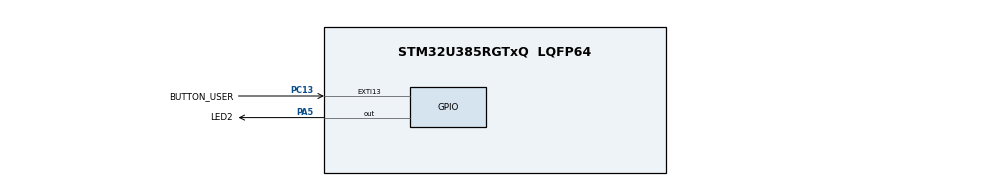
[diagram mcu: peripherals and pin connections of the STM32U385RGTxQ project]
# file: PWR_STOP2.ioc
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CORTEX_M33_NS.userName=CORTEX_M33
Mcu.Family=STM32U3
Mcu.Name=STM32U385RGTxQ
Mcu.Package=LQFP64
NVIC.EXTI13_IRQn=true\:0\:0\:false\:false\:true\:true\:true\:true
NVIC.PriorityGroup=NVIC_PRIORITYGROUP_4
PA5.GPIO_Label=LED2
PA5.Signal=GPIO_Output
PC13.GPIO_Label=BUTTON_USER
PC13.GPIO_ModeDefaultEXTI=GPIO_MODE_IT_RISING
PC13.GPIO_PuPd=GPIO_PULLDOWN
PC13.Signal=GPXTI13
ProjectManager.HeapSize=0x200
ProjectManager.StackSize=0x400
ProjectManager.TargetToolchain=EWARM V9.20
RCC.ADCFreq_Value=96000000
RCC.AHBFreq_Value=96000000
RCC.APB1Freq_Value=96000000
RCC.APB1TimFreq_Value=96000000
RCC.APB2Freq_Value=96000000
RCC.APB2TimFreq_Value=96000000
RCC.APB3Freq_Value=96000000
RCC.CortexFreq_Value=12000000
RCC.HCLKFreq_Value=96000000
RCC.HSE_VALUE=16000000
RCC.HSI48_VALUE=48000000
RCC.HSI_VALUE=16000000
RCC.LSE_VALUE=32768
RCC.LSIDIV_VALUE=32000
RCC.MSISDIV=RCC_MSI_DIV1
RCC.MSI_VALUE=96000000
RCC.PWR_Regulator_Voltage_Scale=PWR_REGULATOR_VOLTAGE_SCALE1
RCC.SYSCLKFreq_VALUE=96000000
RCC.USBFreq_Value=96000000
VP_ICACHE_VS_ICACHE.Mode=DirectMappedCache
VP_PWR_VS_DBSignals.Mode=DisableDeadBatterySignals
VP_PWR_VS_LPOM.Mode=PowerOptimisation
VP_PWR_VS_SECSignals.Mode=Security/Privilege
board=custom

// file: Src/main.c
/* USER CODE BEGIN Header */
/**
  ******************************************************************************
  * @file    PWR/PWR_STOP2/Src/main.c
  * @author  MCD Application Team
  * @brief   This sample code shows how to use STM32U3xx PWR HAL API to enter
  *          and exit the stop 2 mode using RTC.
  ******************************************************************************
  * @attention
  *
  * Copyright (c) 2024 STMicroelectronics.
  * All rights reserved.
  *
  * This software is licensed under terms that can be found in the LICENSE file
  * in the root directory of this software component.
  * If no LICENSE file comes with this software, it is provided AS-IS.
  *
  ******************************************************************************
  */
/* USER CODE END Header */
#include "main.h"

/* USER CODE BEGIN Includes */
#include "stm32u3xx_nucleo.h"
/* USER CODE END Includes */

/* USER CODE BEGIN PV */
/* Private variables ---------------------------------------------------------*/
#define LED_TOGGLE_DELAY         100
static __IO uint32_t TimingDelay;
/* USER CODE END PV */

void SystemClock_Config(void);
static void MX_GPIO_Init(void);
static void MX_ICACHE_Init(void);
/* USER CODE BEGIN PFP */
/* Private function prototypes -----------------------------------------------*/
/* USER CODE END PFP */

int main(void)
{

  /* MCU Configuration--------------------------------------------------------*/

  /* Reset of all peripherals, Initializes the Flash interface and the Systick. */
  HAL_Init();

  /* USER CODE BEGIN Init */

  /* Configure LD2 */
  BSP_LED_Init(LD2);
  /* USER CODE END Init */

  /* Configure the system clock */
  SystemClock_Config();

  /* USER CODE BEGIN SysInit */

  /* Enable the SMPS regulator to improve power efficiency*/
  if(HAL_PWREx_ConfigSupply(PWR_SMPS_SUPPLY) != HAL_OK)
  {
    Error_Handler();
  }

  /* User push-button (External line 13) will be used to wakeup the system from Stop mode */
  BSP_PB_Init(BUTTON_USER, BUTTON_MODE_EXTI);
  /* USER CODE END SysInit */

  /* Initialize all configured peripherals */
  MX_GPIO_Init();
  MX_ICACHE_Init();

  /* Infinite loop */
  while (1)
  {

    /* USER CODE BEGIN 3 */
    /* Insert 5 second delay */
    HAL_Delay(5000);
    /* Turn off LD2 */
    BSP_LED_Off(LD2);

    /* Suspend Tick increment to prevent wakeup by Systick interrupt.         */
    /* Otherwise the Systick interrupt will wake up the device within 1ms     */
    /* (HAL time base).                                                       */
    HAL_SuspendTick();

    /* Enter STOP 2 mode */
    /* A current leakage can be observed while supplying the MCU from an external source and not supplying the STLink
       (unplugged). To fix this leakage, you can configure the pin PA13 as Analog, however, the connection with the
       debugger is lost. */

    HAL_PWR_EnterSTOPMode(PWR_LOWPOWERMODE_STOP2, PWR_STOPENTRY_WFI);

    /* ... STOP 2 mode ... */

    /* Configure the system clock */
    SystemClock_Config();

    /* Resume Tick interrupt if disabled prior to STOP mode entry */
    HAL_ResumeTick();

  }
  /* USER CODE END 3 */
}

void SystemClock_Config(void)
{
  RCC_OscInitTypeDef RCC_OscInitStruct = {0};
  RCC_ClkInitTypeDef RCC_ClkInitStruct = {0};

  /** Enable Epod Booster
  */
  if (HAL_RCCEx_EpodBoosterClkConfig(RCC_EPODBOOSTER_SOURCE_MSIS, RCC_EPODBOOSTER_DIV1) != HAL_OK)
  {
    Error_Handler();
  }
  if (HAL_PWREx_EnableEpodBooster() != HAL_OK)
  {
    Error_Handler();
  }

  /** Configure the main internal regulator output voltage
  */
  if (HAL_PWREx_ControlVoltageScaling(PWR_REGULATOR_VOLTAGE_SCALE1) != HAL_OK)
  {
    Error_Handler();
  }

  /** Set Flash latency before increasing MSIS
  */
  __HAL_FLASH_SET_LATENCY(FLASH_LATENCY_2);

  /** Initializes the CPU, AHB and APB buses clocks
  */
  RCC_OscInitStruct.OscillatorType = RCC_OSCILLATORTYPE_MSIS;
  RCC_OscInitStruct.MSISState = RCC_MSI_ON;
  RCC_OscInitStruct.MSISSource = RCC_MSI_RC0;
  RCC_OscInitStruct.MSISDiv = RCC_MSI_DIV1;
  if (HAL_RCC_OscConfig(&RCC_OscInitStruct) != HAL_OK)
  {
    Error_Handler();
  }

  /** Initializes the CPU, AHB and APB buses clocks
  */
  RCC_ClkInitStruct.ClockType = RCC_CLOCKTYPE_HCLK|RCC_CLOCKTYPE_SYSCLK
                              |RCC_CLOCKTYPE_PCLK1|RCC_CLOCKTYPE_PCLK2
                              |RCC_CLOCKTYPE_PCLK3;
  RCC_ClkInitStruct.SYSCLKSource = RCC_SYSCLKSOURCE_MSIS;
  RCC_ClkInitStruct.AHBCLKDivider = RCC_SYSCLK_DIV1;
  RCC_ClkInitStruct.APB1CLKDivider = RCC_HCLK_DIV1;
  RCC_ClkInitStruct.APB2CLKDivider = RCC_HCLK_DIV1;
  RCC_ClkInitStruct.APB3CLKDivider = RCC_HCLK_DIV1;

  if (HAL_RCC_ClockConfig(&RCC_ClkInitStruct, FLASH_LATENCY_2) != HAL_OK)
  {
    Error_Handler();
  }
}

static void MX_ICACHE_Init(void)
{

  /** Enable instruction cache in 1-way (direct mapped cache)
  */
  if (HAL_ICACHE_ConfigAssociativityMode(ICACHE_1WAY) != HAL_OK)
  {
    Error_Handler();
  }
  if (HAL_ICACHE_Enable() != HAL_OK)
  {
    Error_Handler();
  }

}

static void MX_GPIO_Init(void)
{
  GPIO_InitTypeDef GPIO_InitStruct = {0};

  /* GPIO Ports Clock Enable */
  __HAL_RCC_GPIOC_CLK_ENABLE();
  __HAL_RCC_GPIOA_CLK_ENABLE();

  /*Configure GPIO pin Output Level */
  HAL_GPIO_WritePin(LED2_GPIO_Port, LED2_Pin, GPIO_PIN_RESET);

  /*Configure GPIO pin : BUTTON_USER_Pin */
  GPIO_InitStruct.Pin = BUTTON_USER_Pin;
  GPIO_InitStruct.Mode = GPIO_MODE_IT_RISING;
  GPIO_InitStruct.Pull = GPIO_PULLDOWN;
  HAL_GPIO_Init(BUTTON_USER_GPIO_Port, &GPIO_InitStruct);

  /*Configure GPIO pin : LED2_Pin */
  GPIO_InitStruct.Pin = LED2_Pin;
  GPIO_InitStruct.Mode = GPIO_MODE_OUTPUT_PP;
  GPIO_InitStruct.Pull = GPIO_NOPULL;
  GPIO_InitStruct.Speed = GPIO_SPEED_FREQ_LOW;
  HAL_GPIO_Init(LED2_GPIO_Port, &GPIO_InitStruct);

  /* EXTI interrupt init*/
  HAL_NVIC_SetPriority(EXTI13_IRQn, 0, 0);
  HAL_NVIC_EnableIRQ(EXTI13_IRQn);

}

/* USER CODE BEGIN 4 */

/**
  * @brief SYSTICK callback
  * @param None
  * @retval None
  */
void HAL_SYSTICK_Callback(void)
{
  if (TimingDelay != 0)
  {
    TimingDelay--;
  }
  else
  {
    /* Toggle LD2 */
    BSP_LED_Toggle(LD2);
    TimingDelay = LED_TOGGLE_DELAY;
  }
}

/**
  * @brief EXTI line detection callbacks
  * @param GPIO_Pin: Specifies the pins connected EXTI line
  * @retval None
  */
void HAL_GPIO_EXTI_Rising_Callback(uint16_t GPIO_Pin)
{
  if (GPIO_Pin == BUTTON_USER_PIN)
  {
    /* Reconfigure LD2 */
    BSP_LED_Init(LD2);
   /* Toggle LD2 */
    BSP_LED_Toggle(LD2);
    TimingDelay = LED_TOGGLE_DELAY;
  }
}

/* USER CODE END 4 */

void Error_Handler(void)
{
  /* USER CODE BEGIN Error_Handler_Debug */
  /* Suspend tick */
  HAL_SuspendTick();

  /* Turn LD2 on */
  BSP_LED_On(LD2);
  while (1)
  {
  }
  /* USER CODE END Error_Handler_Debug */
}
